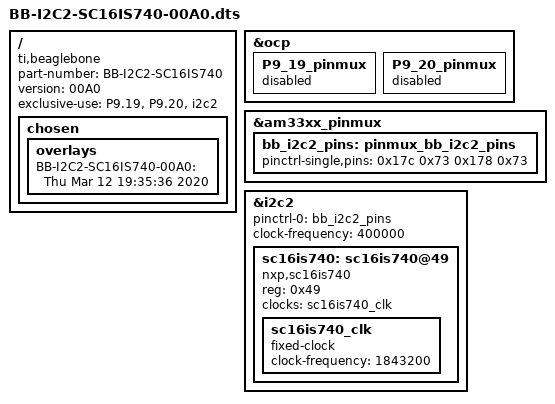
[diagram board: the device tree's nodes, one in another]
/*
 * Virtual cape for I2C2 on connector pins P9.12 P9.19 P9.20
 *
 * This program is free software; you can redistribute it and/or modify
 * it under the terms of the GNU General Public License version 2 as
 * published by the Free Software Foundation.
 */

/dts-v1/;
/plugin/;

/ {
	compatible = "ti,beaglebone", "ti,beaglebone-black";

	// identification
	part-number = "BB-I2C2-SC16IS740";
	version = "00A0";

	// resources this cape uses
	exclusive-use =
		// "P9.12",	// GPIO1_28 = GPIO 60
		"P9.19",	// i2c2_sda
		"P9.20",	// i2c2_scl
		"i2c2";		// hardware ip used

	/*
	 * Helper to show loaded overlays under: /proc/device-tree/chosen/overlays/
	 */
	fragment@0 {
		target-path="/";
		__overlay__ {

			chosen {
				overlays {
					BB-I2C2-SC16IS740-00A0 = "Thu Mar 12 19:35:36 2020";
				};
			};
		};
	};

	/*
	 * Free up the pins used by the cape from the pinmux helpers.
	 */
	fragment@1 {
		target = <&ocp>;
		__overlay__ {
			// P9_12_pinmux { status = "disabled"; };	/* GPIO 60 */
			P9_19_pinmux { status = "disabled"; };	/* i2c2_scl */
			P9_20_pinmux { status = "disabled"; };	/* i2c2_sda */
		};
	};

	fragment@2 {
		target = <&am33xx_pinmux>;
		__overlay__ {
			bb_i2c2_pins: pinmux_bb_i2c2_pins {
				pinctrl-single,pins = <
					// 0x078 0x3f	/* (PIN_OUTPUT_PULLUP | MUX_MODE7) GPIO1_28 */
					0x17c 0x73	/* i2c2_sda, SLEWCTRL_SLOW | INPUT_PULLUP | MODE3 */
					0x178 0x73	/* i2c2_scl, SLEWCTRL_SLOW | INPUT_PULLUP | MODE3 */
				>;
				linux,phandle = <0x00000001>;
				phandle = <0x00000001>;
			};
		};
	};

	fragment@3 {
		target = <&i2c2>;
		__overlay__ {
			status = "okay";
			pinctrl-names = "default";
			pinctrl-0 = <&bb_i2c2_pins>;

			/* this is the configuration part */
			clock-frequency = <400000>;

			#address-cells = <1>;
			#size-cells = <0>;

			/* add any i2c devices on the bus here */
		};
	};

	fragment@4 {
		target = <&i2c2>;
		__overlay__ {
			#address-cells = <1>;
			#size-cells = <0>;
			status = "okay";

			sc16is740: sc16is740@49 {
				compatible = "nxp,sc16is740";
				reg = <0x49>; /* address */
				clocks = <&sc16is740_clk>;
				// interrupt-parent = <&gpio>;
				// interrupts = <48 2>; /* IRQ_TYPE_FALLING_EDGE */
				#gpio-cells = <2>;

				sc16is740_clk: sc16is740_clk {
					compatible = "fixed-clock";
					#clock-cells = <0>;
					clock-frequency = <1843200>;
				};
			};
		};
	};
};
